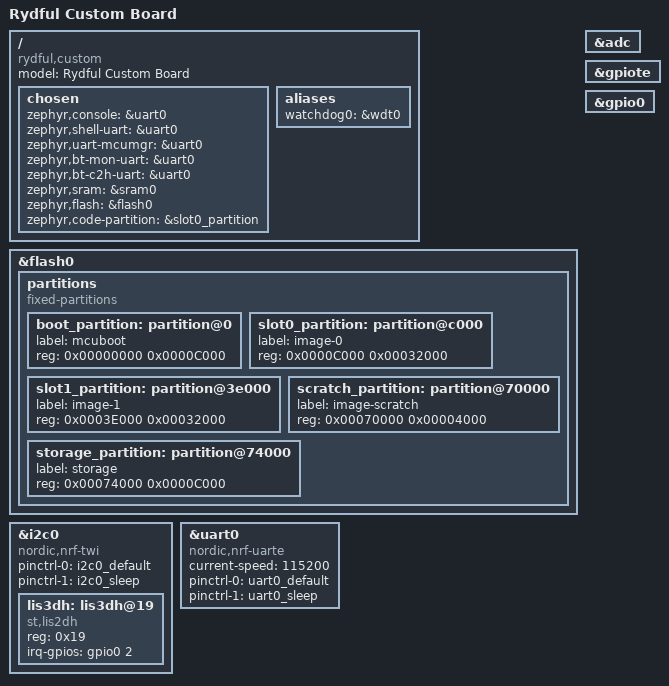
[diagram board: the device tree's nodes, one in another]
/*
 * SPDX-License-Identifier: Apache-2.0
 *
 * Rydful Custom PCB - nRF52832 with LIS3DHTR accelerometer
 */

/dts-v1/;
#include <nordic/nrf52832_qfaa.dtsi>
#include "rydful_custom-pinctrl.dtsi"

/ {
	model = "Rydful Custom Board";
	compatible = "rydful,custom";

	chosen {
		zephyr,console = &uart0;
		zephyr,shell-uart = &uart0;
		zephyr,uart-mcumgr = &uart0;
		zephyr,bt-mon-uart = &uart0;
		zephyr,bt-c2h-uart = &uart0;
		zephyr,sram = &sram0;
		zephyr,flash = &flash0;
		zephyr,code-partition = &slot0_partition;
	};

	aliases {
		watchdog0 = &wdt0;
	};
};

&flash0 {
	partitions {
		compatible = "fixed-partitions";
		#address-cells = <1>;
		#size-cells = <1>;

		/* Bootloader (optional, 48KB) */
		boot_partition: partition@0 {
			label = "mcuboot";
			reg = <0x00000000 0x0000C000>;
		};

		/* Application slot 0 (200KB) */
		slot0_partition: partition@c000 {
			label = "image-0";
			reg = <0x0000C000 0x00032000>;
		};

		/* Application slot 1 for OTA (200KB) */
		slot1_partition: partition@3e000 {
			label = "image-1";
			reg = <0x0003E000 0x00032000>;
		};

		/* Scratch partition for swap (16KB) */
		scratch_partition: partition@70000 {
			label = "image-scratch";
			reg = <0x00070000 0x00004000>;
		};

		/* Storage partition (56KB) */
		storage_partition: partition@74000 {
			label = "storage";
			reg = <0x00074000 0x0000C000>;
		};
	};
};

&adc {
	status = "okay";
};

&gpiote {
	status = "okay";
};

&gpio0 {
	status = "okay";
};

/* I2C0 for LIS3DHTR accelerometer */
&i2c0 {
	compatible = "nordic,nrf-twi";
	status = "okay";
	pinctrl-0 = <&i2c0_default>;
	pinctrl-1 = <&i2c0_sleep>;
	pinctrl-names = "default", "sleep";

	lis3dh: lis3dh@19 {
		compatible = "st,lis2dh";
		reg = <0x19>;
		irq-gpios = <&gpio0 2 GPIO_ACTIVE_HIGH>;
		status = "okay";
	};
};

/* UART0 for debugging (directly on pins, no USB) */
&uart0 {
	compatible = "nordic,nrf-uarte";
	status = "okay";
	current-speed = <115200>;
	pinctrl-0 = <&uart0_default>;
	pinctrl-1 = <&uart0_sleep>;
	pinctrl-names = "default", "sleep";
};
